AUTOSAR XML (schema 3-2-1)
package /SeatHeater/SeatHeatingController_swc
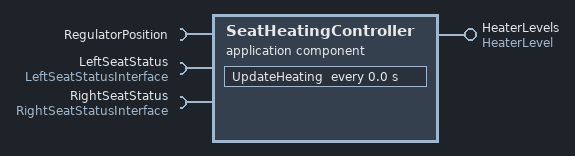
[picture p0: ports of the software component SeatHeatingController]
  application software component type SeatHeatingController
    require port RegulatorPosition: unqueued-provider-com-spec{data-element=Position, alive-timeout=60.0}, provided-interface=RegulatorPosition
    provide port HeaterLevels: provided-com-specs=[{data-element=LeftHeatLevel, alive-timeout=60.0}, {data-element=RightHeatLevel, alive-timeout=60.0}], provided-interface=HeaterLevel
    require port LeftSeatStatus: unqueued-provider-com-spec{data-element=PassengerOnLeftSeat, alive-timeout=60.0}, provided-interface=LeftSeatStatusInterface
    require port RightSeatStatus: unqueued-provider-com-spec{data-element=PassengerOnRightSeat, alive-timeout=60.0}, provided-interface=RightSeatStatusInterface
  internal behavior SeatHeatingControllerBehavior: component=SeatHeatingController
    timing event HeatingUpdateEvent: start-on-event=UpdateHeating, period=0.0
    runnable UpdateHeating: can-be-invoked-concurrently=true
      data read access RegulatorPositionAccess: data-element=RegulatorPosition.Position
      data read access RightSeatStatusAccess: data-element=RightSeatStatus.PassengerOnRightSeat
      data read access LeftSeatStatusAccess: data-element=LeftSeatStatus.PassengerOnLeftSeat
      data write access HeaterRightLevelAccess: data-element=HeaterLevels.RightHeatLevel
      data write access HeaterLeftLevelAccess: data-element=HeaterLevels.LeftHeatLevel
  swc implementation SeatHeatingControllerImplementation: behavior=SeatHeatingControllerBehavior
